# STM32H747ZIY6@M4 register map
File version: 1.0
Registers are 32-bit, access not given, reset 0x0 unless marked. A register's access mark holds for its fields unless they carry their own. Offsets are from the block's base; [hi:lo] are bit positions; {n}, {i} and the like mark numbered series.

## IWDG1
Base 0x58004800
Same registers: IWDG2 0x58004C00
0x00 KR
  [15:0] KEY
0x04 PR
  [2:0] PR
0x08 RLR
  [11:0] RL
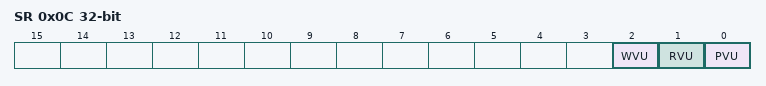
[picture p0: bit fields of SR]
0x0C SR
  [2] WVU, [1] RVU, [0] PVU
0x10 WINR
  [11:0] WIN

## GPIOA
Base 0x58020000
Same registers: GPIOB 0x58020400, GPIOC 0x58020800, GPIOD 0x58020C00, GPIOE 0x58021000, GPIOF 0x58021400, GPIOG 0x58021800, GPIOH 0x58021C00, GPIOI 0x58022000, GPIOJ 0x58022400, GPIOK 0x58022800
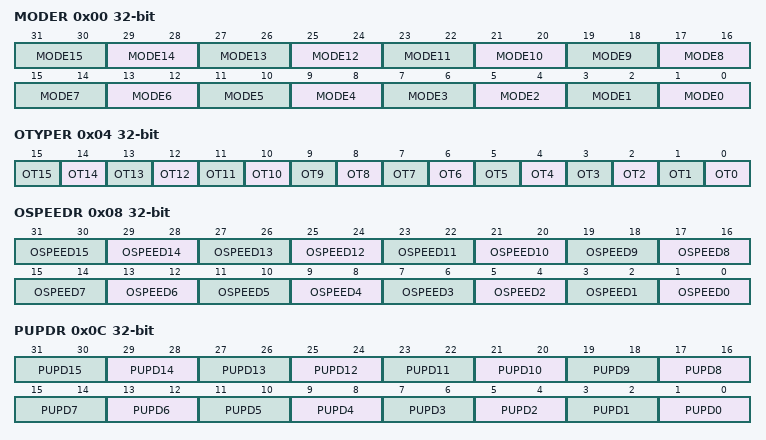
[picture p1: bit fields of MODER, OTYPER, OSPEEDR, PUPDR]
0x00 MODER
  [2n+1:2n] MODE{n} (n=0..15)
0x04 OTYPER
  [n] OT{n} (n=0..15)
0x08 OSPEEDR
  [2n+1:2n] OSPEED{n} (n=0..15)
0x0C PUPDR
  [2n+1:2n] PUPD{n} (n=0..15)
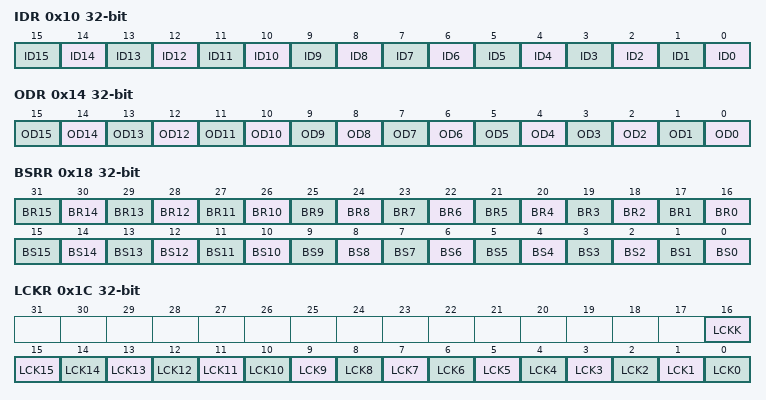
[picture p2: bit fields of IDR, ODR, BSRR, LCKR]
0x10 IDR
  [n] ID{n} (n=0..15)
0x14 ODR
  [n] OD{n} (n=0..15)
0x18 BSRR
  [n+16] BR{n} (n=0..15), [n] BS{n} (n=0..15)
0x1C LCKR
  [16] LCKK, [n] LCK{n} (n=0..15)
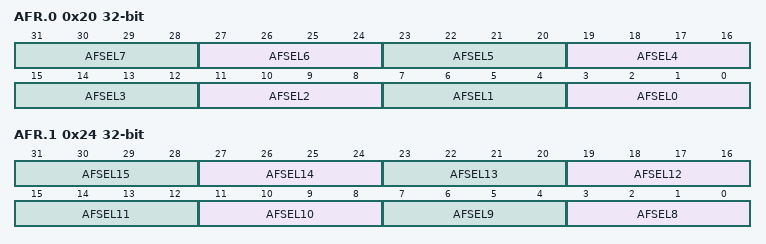
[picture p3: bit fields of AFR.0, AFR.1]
0x20 AFR.0
  [4n+3:4n] AFSEL{n} (n=0..7)
0x24 AFR.1
  [4n-29:4n-32] AFSEL{n} (n=8..15)

## RCC_C1
Base 0x58024530
Same registers: RCC_C2 0x58024590
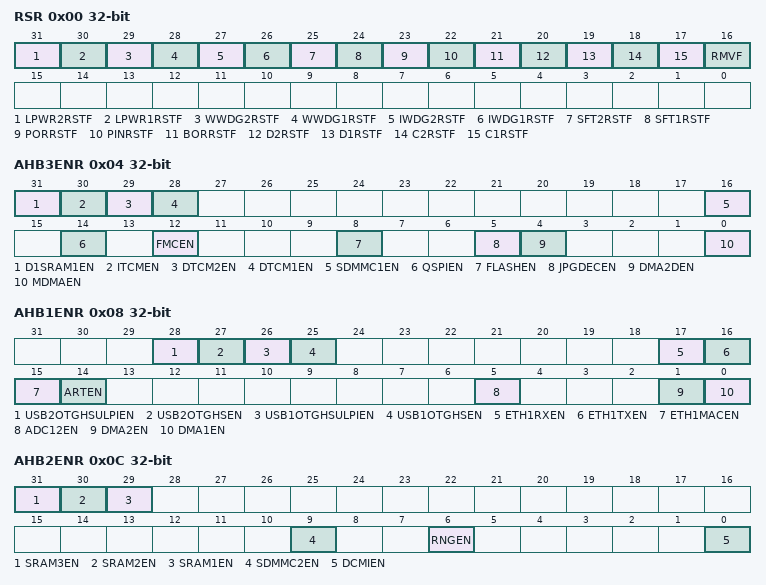
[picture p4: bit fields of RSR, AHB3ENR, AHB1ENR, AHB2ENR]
0x00 RSR
  [31] LPWR2RSTF, [30] LPWR1RSTF, [29] WWDG2RSTF, [28] WWDG1RSTF, [27] IWDG2RSTF, [26] IWDG1RSTF, [25] SFT2RSTF, [24] SFT1RSTF, [23] PORRSTF, [22] PINRSTF, [21] BORRSTF, [20] D2RSTF, [19] D1RSTF, [18] C2RSTF, [17] C1RSTF, [16] RMVF
0x04 AHB3ENR
  [31] D1SRAM1EN, [30] ITCMEN, [29] DTCM2EN, [28] DTCM1EN, [16] SDMMC1EN, [14] QSPIEN, [12] FMCEN, [8] FLASHEN, [5] JPGDECEN, [4] DMA2DEN, [0] MDMAEN
0x08 AHB1ENR
  [28] USB2OTGHSULPIEN, [27] USB2OTGHSEN, [26] USB1OTGHSULPIEN, [25] USB1OTGHSEN, [17] ETH1RXEN, [16] ETH1TXEN, [15] ETH1MACEN, [14] ARTEN, [5] ADC12EN, [1] DMA2EN, [0] DMA1EN
0x0C AHB2ENR
  [31] SRAM3EN, [30] SRAM2EN, [29] SRAM1EN, [9] SDMMC2EN, [6] RNGEN, [0] DCMIEN
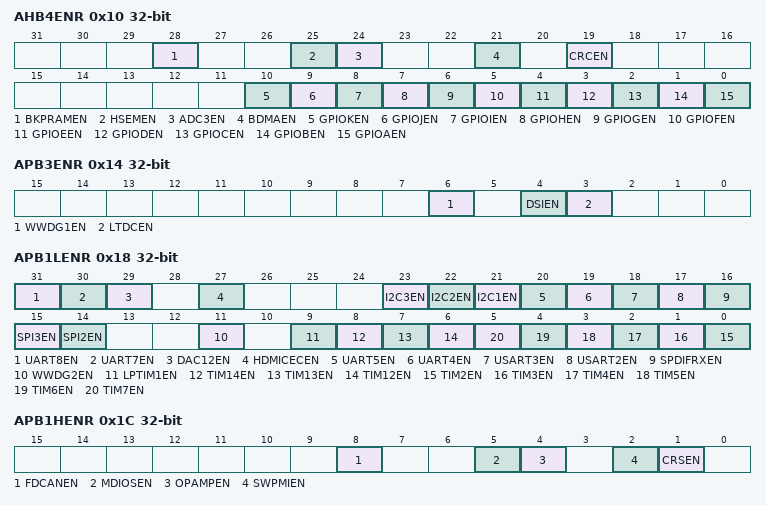
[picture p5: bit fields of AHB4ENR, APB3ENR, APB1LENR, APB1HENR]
0x10 AHB4ENR
  [28] BKPRAMEN, [25] HSEMEN, [24] ADC3EN, [21] BDMAEN, [19] CRCEN, [10] GPIOKEN, [9] GPIOJEN, [8] GPIOIEN, [7] GPIOHEN, [6] GPIOGEN, [5] GPIOFEN, [4] GPIOEEN, [3] GPIODEN, [2] GPIOCEN, [1] GPIOBEN, [0] GPIOAEN
0x14 APB3ENR
  [6] WWDG1EN, [4] DSIEN, [3] LTDCEN
0x18 APB1LENR
  [31] UART8EN, [30] UART7EN, [29] DAC12EN, [27] HDMICECEN, [23] I2C3EN, [22] I2C2EN, [21] I2C1EN, [20] UART5EN, [19] UART4EN, [18] USART3EN, [17] USART2EN, [16] SPDIFRXEN, [15] SPI3EN, [14] SPI2EN, [11] WWDG2EN, [9] LPTIM1EN, [8] TIM14EN, [7] TIM13EN, [6] TIM12EN, [n-2] TIM{n}EN (n=2..7)
0x1C APB1HENR
  [8] FDCANEN, [5] MDIOSEN, [4] OPAMPEN, [2] SWPMIEN, [1] CRSEN
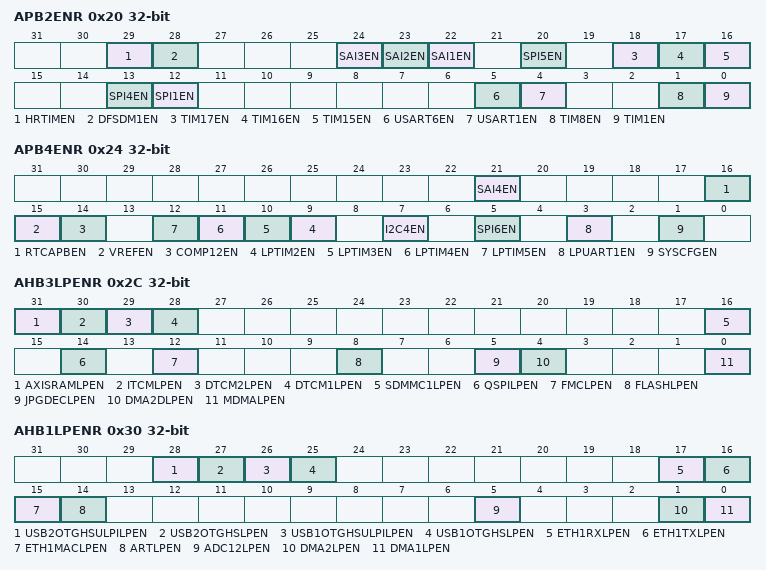
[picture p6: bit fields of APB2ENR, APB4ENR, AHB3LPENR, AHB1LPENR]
0x20 APB2ENR
  [29] HRTIMEN, [28] DFSDM1EN, [24] SAI3EN, [23] SAI2EN, [22] SAI1EN, [20] SPI5EN, [18] TIM17EN, [17] TIM16EN, [16] TIM15EN, [13] SPI4EN, [12] SPI1EN, [5] USART6EN, [4] USART1EN, [1] TIM8EN, [0] TIM1EN
0x24 APB4ENR
  [21] SAI4EN, [16] RTCAPBEN, [15] VREFEN, [14] COMP12EN, [n+7] LPTIM{n}EN (n=2..5), [7] I2C4EN, [5] SPI6EN, [3] LPUART1EN, [1] SYSCFGEN
0x2C AHB3LPENR
  [31] AXISRAMLPEN, [30] ITCMLPEN, [29] DTCM2LPEN, [28] DTCM1LPEN, [16] SDMMC1LPEN, [14] QSPILPEN, [12] FMCLPEN, [8] FLASHLPEN, [5] JPGDECLPEN, [4] DMA2DLPEN, [0] MDMALPEN
0x30 AHB1LPENR
  [28] USB2OTGHSULPILPEN, [27] USB2OTGHSLPEN, [26] USB1OTGHSULPILPEN, [25] USB1OTGHSLPEN, [17] ETH1RXLPEN, [16] ETH1TXLPEN, [15] ETH1MACLPEN, [14] ARTLPEN, [5] ADC12LPEN, [1] DMA2LPEN, [0] DMA1LPEN
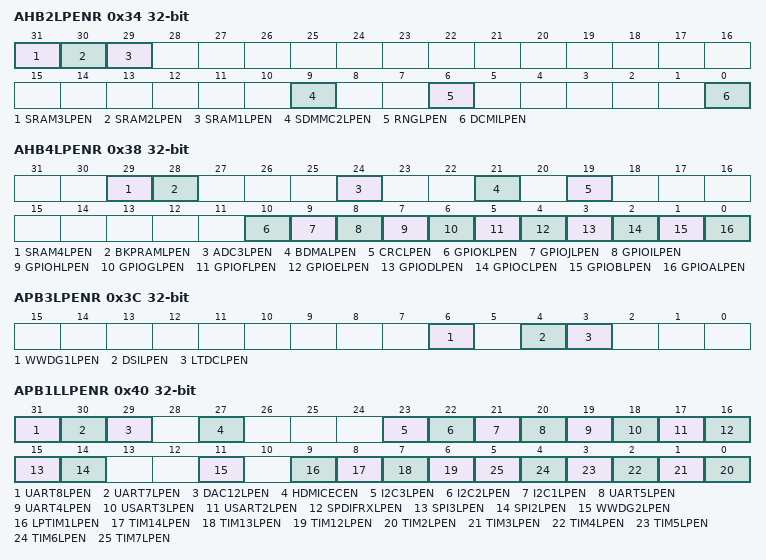
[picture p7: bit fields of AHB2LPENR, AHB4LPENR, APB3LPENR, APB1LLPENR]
0x34 AHB2LPENR
  [31] SRAM3LPEN, [30] SRAM2LPEN, [29] SRAM1LPEN, [9] SDMMC2LPEN, [6] RNGLPEN, [0] DCMILPEN
0x38 AHB4LPENR
  [29] SRAM4LPEN, [28] BKPRAMLPEN, [24] ADC3LPEN, [21] BDMALPEN, [19] CRCLPEN, [10] GPIOKLPEN, [9] GPIOJLPEN, [8] GPIOILPEN, [7] GPIOHLPEN, [6] GPIOGLPEN, [5] GPIOFLPEN, [4] GPIOELPEN, [3] GPIODLPEN, [2] GPIOCLPEN, [1] GPIOBLPEN, [0] GPIOALPEN
0x3C APB3LPENR
  [6] WWDG1LPEN, [4] DSILPEN, [3] LTDCLPEN
0x40 APB1LLPENR
  [31] UART8LPEN, [30] UART7LPEN, [29] DAC12LPEN, [27] HDMICECEN, [23] I2C3LPEN, [22] I2C2LPEN, [21] I2C1LPEN, [20] UART5LPEN, [19] UART4LPEN, [18] USART3LPEN, [17] USART2LPEN, [16] SPDIFRXLPEN, [15] SPI3LPEN, [14] SPI2LPEN, [11] WWDG2LPEN, [9] LPTIM1LPEN, [8] TIM14LPEN, [7] TIM13LPEN, [6] TIM12LPEN, [n-2] TIM{n}LPEN (n=2..7)
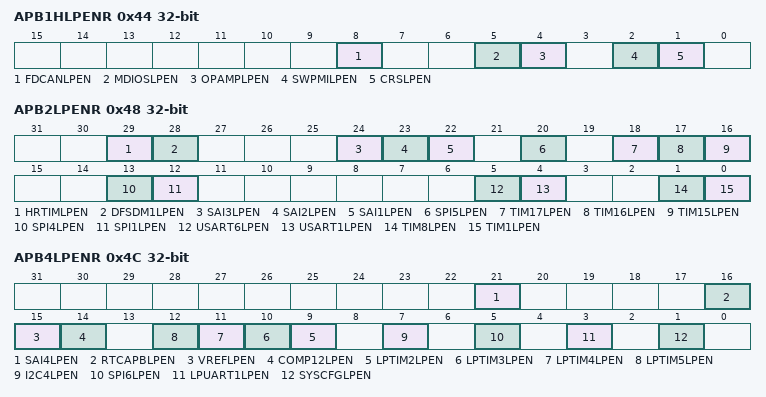
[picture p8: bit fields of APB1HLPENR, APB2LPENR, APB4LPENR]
0x44 APB1HLPENR
  [8] FDCANLPEN, [5] MDIOSLPEN, [4] OPAMPLPEN, [2] SWPMILPEN, [1] CRSLPEN
0x48 APB2LPENR
  [29] HRTIMLPEN, [28] DFSDM1LPEN, [24] SAI3LPEN, [23] SAI2LPEN, [22] SAI1LPEN, [20] SPI5LPEN, [18] TIM17LPEN, [17] TIM16LPEN, [16] TIM15LPEN, [13] SPI4LPEN, [12] SPI1LPEN, [5] USART6LPEN, [4] USART1LPEN, [1] TIM8LPEN, [0] TIM1LPEN
0x4C APB4LPENR
  [21] SAI4LPEN, [16] RTCAPBLPEN, [15] VREFLPEN, [14] COMP12LPEN, [n+7] LPTIM{n}LPEN (n=2..5), [7] I2C4LPEN, [5] SPI6LPEN, [3] LPUART1LPEN, [1] SYSCFGLPEN
